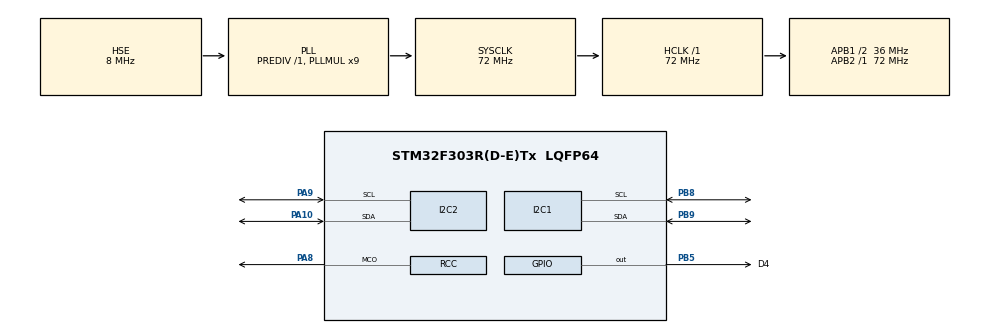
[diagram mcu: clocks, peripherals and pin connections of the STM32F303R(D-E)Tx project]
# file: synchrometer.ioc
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FREERTOS.Tasks01=defaultTask,0,128,StartDefaultTask,Default;ledTask,-3,256,ld2FlashTask,Default
Mcu.Family=STM32F3
Mcu.Name=STM32F303R(D-E)Tx
Mcu.Package=LQFP64
NVIC.I2C2_ER_IRQn=true\:5\:0\:false
NVIC.I2C2_EV_IRQn=true\:5\:0\:false
NVIC.PriorityGroup=NVIC_PRIORITYGROUP_4
NVIC.TIM1_UP_TIM16_IRQn=true\:0\:0\:false
NVIC.TimeBase=TIM1_UP_TIM16_IRQn
NVIC.TimeBaseIP=TIM1
PA10.Mode=I2C
PA10.Signal=I2C2_SDA
PA13.Mode=JTAG(5-pin)
PA13.Signal=SYS_JTMS-SWDIO
PA14.Mode=JTAG(5-pin)
PA14.Signal=SYS_JTCK-SWCLK
PA15.Mode=JTAG(5-pin)
PA15.Signal=SYS_JTDI
PA8.Mode=Clock-out
PA8.Signal=RCC_MCO
PA9.Mode=I2C
PA9.Signal=I2C2_SCL
PB3.Mode=JTAG(5-pin)
PB3.Signal=SYS_JTDO-TRACESWO
PB4.Mode=JTAG(5-pin)
PB4.Signal=SYS_NJTRST
PB5.GPIO_Label=D4
PB5.Signal=GPIO_Output
PB8.Mode=I2C
PB8.Signal=I2C1_SCL
PB9.Mode=I2C
PB9.Signal=I2C1_SDA
PF0-OSC_IN.Mode=HSE-External-Oscillator
PF0-OSC_IN.Signal=RCC_OSC_IN
PF1-OSC_OUT.Mode=HSE-External-Oscillator
PF1-OSC_OUT.Signal=RCC_OSC_OUT
ProjectManager.HeapSize=0x400
ProjectManager.StackSize=0x200
ProjectManager.TargetToolchain=SW4STM32
RCC.AHBFreq_Value=72000000
RCC.APB1CLKDivider=RCC_HCLK_DIV2
RCC.APB1Freq_Value=36000000
RCC.APB1TimFreq_Value=72000000
RCC.APB2Freq_Value=72000000
RCC.APB2TimFreq_Value=72000000
RCC.CortexFreq_Value=72000000
RCC.HCLKFreq_Value=72000000
RCC.HSE_VALUE=8000000
RCC.HSI_VALUE=8000000
RCC.LSE_VALUE=32768
RCC.PLLMUL=RCC_PLL_MUL9
RCC.PLLSourceVirtual=RCC_PLLSOURCE_HSE
RCC.SYSCLKFreq_VALUE=72000000
RCC.SYSCLKSourceVirtual=RCC_SYSCLKSOURCE_PLLCLK
RCC.USBFreq_Value=72000000
VP_FREERTOS_VS_ENABLE.Mode=Enabled
VP_SYS_VS_tim1.Mode=TIM1
board=synchrometer

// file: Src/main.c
/**
  ******************************************************************************
  * File Name          : main.c
  * Description        : Main program body
  ******************************************************************************
  *
  * COPYRIGHT(c) 2016 STMicroelectronics
  *
  * Redistribution and use in source and binary forms, with or without modification,
  * are permitted provided that the following conditions are met:
  *   1. Redistributions of source code must retain the above copyright notice,
  *      this list of conditions and the following disclaimer.
  *   2. Redistributions in binary form must reproduce the above copyright notice,
  *      this list of conditions and the following disclaimer in the documentation
  *      and/or other materials provided with the distribution.
  *   3. Neither the name of STMicroelectronics nor the names of its contributors
  *      may be used to endorse or promote products derived from this software
  *      without specific prior written permission.
  *
  * THIS SOFTWARE IS PROVIDED BY THE COPYRIGHT HOLDERS AND CONTRIBUTORS "AS IS"
  * AND ANY EXPRESS OR IMPLIED WARRANTIES, INCLUDING, BUT NOT LIMITED TO, THE
  * IMPLIED WARRANTIES OF MERCHANTABILITY AND FITNESS FOR A PARTICULAR PURPOSE ARE
  * DISCLAIMED. IN NO EVENT SHALL THE COPYRIGHT HOLDER OR CONTRIBUTORS BE LIABLE
  * FOR ANY DIRECT, INDIRECT, INCIDENTAL, SPECIAL, EXEMPLARY, OR CONSEQUENTIAL
  * DAMAGES (INCLUDING, BUT NOT LIMITED TO, PROCUREMENT OF SUBSTITUTE GOODS OR
  * SERVICES; LOSS OF USE, DATA, OR PROFITS; OR BUSINESS INTERRUPTION) HOWEVER
  * CAUSED AND ON ANY THEORY OF LIABILITY, WHETHER IN CONTRACT, STRICT LIABILITY,
  * OR TORT (INCLUDING NEGLIGENCE OR OTHERWISE) ARISING IN ANY WAY OUT OF THE USE
  * OF THIS SOFTWARE, EVEN IF ADVISED OF THE POSSIBILITY OF SUCH DAMAGE.
  *
  ******************************************************************************
  */
#include "stm32f3xx_hal.h"
#include "cmsis_os.h"
#include "i2c.h"
#include "gpio.h"

/* USER CODE BEGIN PV */
#define AP_START_SECTOR 0x08010000
#define NVIC_VectTab_FLASH      (0x00000000)

/* Private variables ---------------------------------------------------------*/

/* USER CODE END PV */

void SystemClock_Config(void);
void MX_FREERTOS_Init(void);

/* USER CODE BEGIN PFP */
/* Private function prototypes -----------------------------------------------*/

/* USER CODE END PFP */

/* USER CODE BEGIN 0 */
const char VERSION[] = "1.0";

/* USER CODE END 0 */

int main(void)
{

  /* USER CODE BEGIN 1 */

	// Relocate the ISR.
	SCB->VTOR = NVIC_VectTab_FLASH | AP_START_SECTOR;

  /* USER CODE END 1 */

  /* MCU Configuration----------------------------------------------------------*/

  /* Reset of all peripherals, Initializes the Flash interface and the Systick. */
  HAL_Init();

  /* Configure the system clock */
  SystemClock_Config();

  /* Initialize all configured peripherals */
  MX_GPIO_Init();
  MX_I2C1_Init();
  MX_I2C2_Init();

  /* Call init function for freertos objects (in freertos.c) */
  MX_FREERTOS_Init();

  /* Start scheduler */
  osKernelStart();

  /* We should never get here as control is now taken by the scheduler */

  /* Infinite loop */
  while (1)
  {

  }

}

/** System Clock Configuration
*/
void SystemClock_Config(void)
{

  RCC_OscInitTypeDef RCC_OscInitStruct;
  RCC_ClkInitTypeDef RCC_ClkInitStruct;
  RCC_PeriphCLKInitTypeDef PeriphClkInit;

  RCC_OscInitStruct.OscillatorType = RCC_OSCILLATORTYPE_HSI|RCC_OSCILLATORTYPE_HSE;
  RCC_OscInitStruct.HSEState = RCC_HSE_ON;
  RCC_OscInitStruct.HSIState = RCC_HSI_ON;
  RCC_OscInitStruct.HSICalibrationValue = 16;
  RCC_OscInitStruct.PLL.PLLState = RCC_PLL_ON;
  RCC_OscInitStruct.PLL.PLLSource = RCC_PLLSOURCE_HSE;
  RCC_OscInitStruct.PLL.PLLMUL = RCC_PLL_MUL9;
  RCC_OscInitStruct.PLL.PREDIV = RCC_PREDIV_DIV1;
  HAL_RCC_OscConfig(&RCC_OscInitStruct);

  RCC_ClkInitStruct.ClockType = RCC_CLOCKTYPE_HCLK|RCC_CLOCKTYPE_SYSCLK
                              |RCC_CLOCKTYPE_PCLK1|RCC_CLOCKTYPE_PCLK2;
  RCC_ClkInitStruct.SYSCLKSource = RCC_SYSCLKSOURCE_PLLCLK;
  RCC_ClkInitStruct.AHBCLKDivider = RCC_SYSCLK_DIV1;
  RCC_ClkInitStruct.APB1CLKDivider = RCC_HCLK_DIV2;
  RCC_ClkInitStruct.APB2CLKDivider = RCC_HCLK_DIV1;
  HAL_RCC_ClockConfig(&RCC_ClkInitStruct, FLASH_LATENCY_2);

  PeriphClkInit.PeriphClockSelection = RCC_PERIPHCLK_I2C1|RCC_PERIPHCLK_I2C2
                              |RCC_PERIPHCLK_TIM20;
  PeriphClkInit.I2c1ClockSelection = RCC_I2C1CLKSOURCE_HSI;
  PeriphClkInit.I2c2ClockSelection = RCC_I2C2CLKSOURCE_HSI;
  PeriphClkInit.Tim20ClockSelection = RCC_TIM20CLK_HCLK;
  HAL_RCCEx_PeriphCLKConfig(&PeriphClkInit);

  HAL_RCC_MCOConfig(RCC_MCO, RCC_MCOSOURCE_SYSCLK, RCC_MCO_DIV1);

  HAL_SYSTICK_Config(HAL_RCC_GetHCLKFreq()/1000);

  HAL_SYSTICK_CLKSourceConfig(SYSTICK_CLKSOURCE_HCLK);

  /* SysTick_IRQn interrupt configuration */
  HAL_NVIC_SetPriority(SysTick_IRQn, 15, 0);
}

/************************ (C) COPYRIGHT STMicroelectronics *****END OF FILE****/

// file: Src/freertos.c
/**
  ******************************************************************************
  * File Name          : freertos.c
  * Description        : Code for freertos applications
  ******************************************************************************
  *
  * COPYRIGHT(c) 2016 STMicroelectronics
  *
  * Redistribution and use in source and binary forms, with or without modification,
  * are permitted provided that the following conditions are met:
  *   1. Redistributions of source code must retain the above copyright notice,
  *      this list of conditions and the following disclaimer.
  *   2. Redistributions in binary form must reproduce the above copyright notice,
  *      this list of conditions and the following disclaimer in the documentation
  *      and/or other materials provided with the distribution.
  *   3. Neither the name of STMicroelectronics nor the names of its contributors
  *      may be used to endorse or promote products derived from this software
  *      without specific prior written permission.
  *
  * THIS SOFTWARE IS PROVIDED BY THE COPYRIGHT HOLDERS AND CONTRIBUTORS "AS IS"
  * AND ANY EXPRESS OR IMPLIED WARRANTIES, INCLUDING, BUT NOT LIMITED TO, THE
  * IMPLIED WARRANTIES OF MERCHANTABILITY AND FITNESS FOR A PARTICULAR PURPOSE ARE
  * DISCLAIMED. IN NO EVENT SHALL THE COPYRIGHT HOLDER OR CONTRIBUTORS BE LIABLE
  * FOR ANY DIRECT, INDIRECT, INCIDENTAL, SPECIAL, EXEMPLARY, OR CONSEQUENTIAL
  * DAMAGES (INCLUDING, BUT NOT LIMITED TO, PROCUREMENT OF SUBSTITUTE GOODS OR
  * SERVICES; LOSS OF USE, DATA, OR PROFITS; OR BUSINESS INTERRUPTION) HOWEVER
  * CAUSED AND ON ANY THEORY OF LIABILITY, WHETHER IN CONTRACT, STRICT LIABILITY,
  * OR TORT (INCLUDING NEGLIGENCE OR OTHERWISE) ARISING IN ANY WAY OUT OF THE USE
  * OF THIS SOFTWARE, EVEN IF ADVISED OF THE POSSIBILITY OF SUCH DAMAGE.
  *
  ******************************************************************************
  */

#include "FreeRTOS.h"
#include "task.h"
#include "cmsis_os.h"

/* USER CODE BEGIN Includes */
#include "gpio.h"

/* USER CODE END Includes */

osThreadId defaultTaskHandle;
osThreadId ledTaskHandle;

void StartDefaultTask(void const * argument);
void ld2FlashTask(void const * argument);

void MX_FREERTOS_Init(void); /* (MISRA C 2004 rule 8.1) */

/* Hook prototypes */

/* Init FreeRTOS */

void MX_FREERTOS_Init(void) {

  /* Create the thread(s) */
  /* definition and creation of defaultTask */
  osThreadDef(defaultTask, StartDefaultTask, osPriorityNormal, 0, 128);
  defaultTaskHandle = osThreadCreate(osThread(defaultTask), NULL);

  /* definition and creation of ledTask */
  osThreadDef(ledTask, ld2FlashTask, osPriorityIdle, 0, 256);
  ledTaskHandle = osThreadCreate(osThread(ledTask), NULL);

}

/* StartDefaultTask function */
void StartDefaultTask(void const * argument)
{

  for(;;)
  {
    osDelay(1);
  }
}

/* ld2FlashTask function */
void ld2FlashTask(void const * argument)
{
  /* USER CODE BEGIN ld2FlashTask */
	uint8_t flashFlag;
	GPIO_PinState outputState;
	flashFlag = 0;
  /* Infinite loop */
  for(;;)
  {
	  // Delay 250mS
    osDelay(250);

    // Toggle LED flag and set output state
    flashFlag = 1 - flashFlag;
    outputState = (flashFlag==0) ? GPIO_PIN_RESET : GPIO_PIN_SET;

    // Output Logic state
    HAL_GPIO_WritePin(D4_GPIO_Port, D4_Pin, outputState);

  }
  /* USER CODE END ld2FlashTask */
}

/************************ (C) COPYRIGHT STMicroelectronics *****END OF FILE****/
